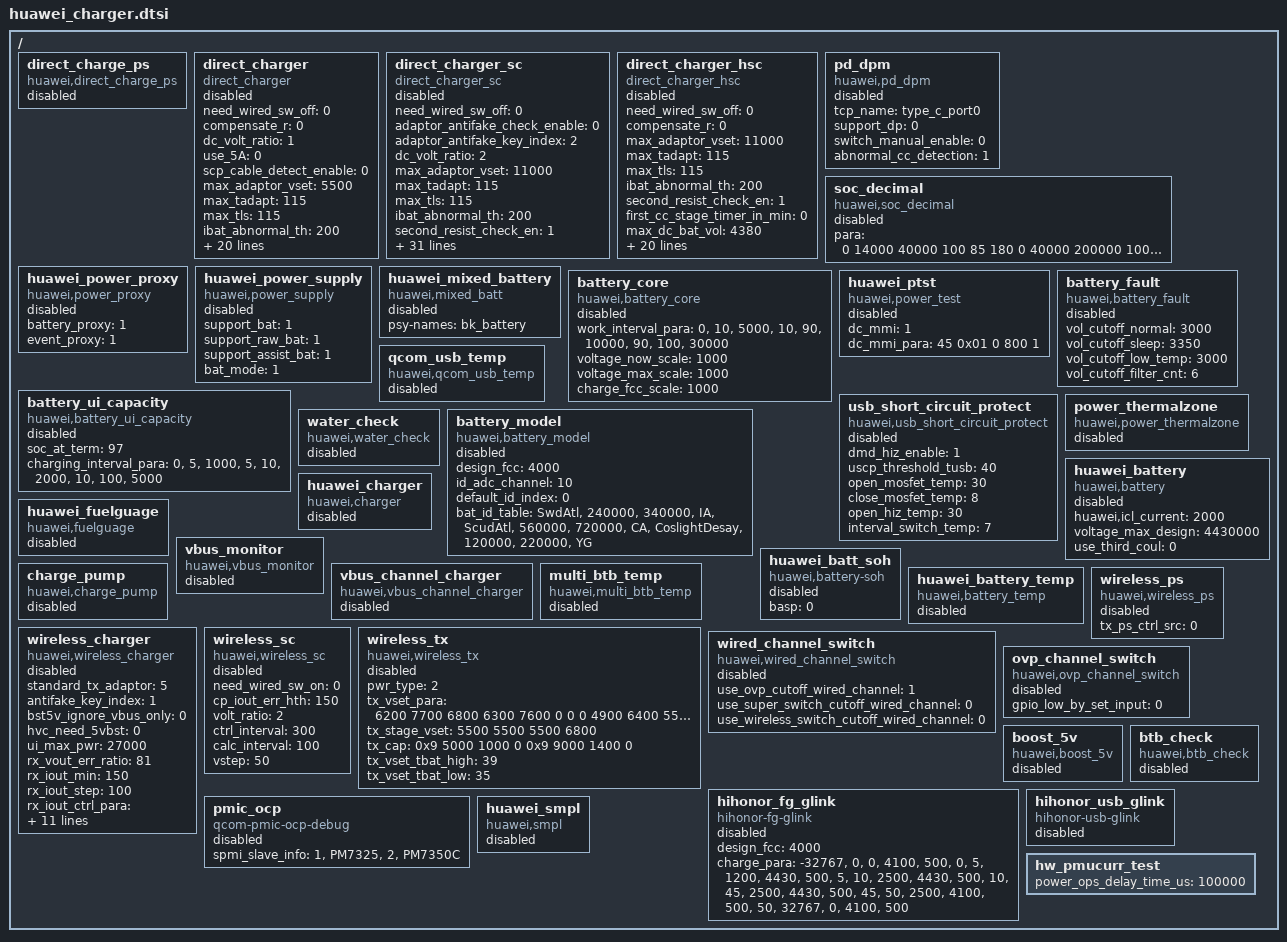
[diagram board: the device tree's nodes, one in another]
/ {
    direct_charge_ps:direct_charge_ps {
		compatible = "huawei,direct_charge_ps";
		status = "disabled";
	};

	direct_charger: direct_charger{
		need_wired_sw_off = <0>;
		compensate_r = <0>;
		dc_volt_ratio = <1>;
		use_5A = <0>;
		scp_cable_detect_enable = <0>;
		max_adaptor_vset = <5500>;
		max_tadapt = <115>;
		max_tls = <115>;
		ibat_abnormal_th = <200>;
		first_cc_stage_timer_in_min = <0>;
		max_dc_bat_vol = <4350>;
		min_dc_bat_vol = <3550>;
		is_align_caculation_work = <0>;
		charge_control_interval = <5>;
		threshold_caculation_interval = <5>;
		safety_monitor_interval = <5>;
		scp_work_on_charger = <0>;
		init_adapter_vset = <4400>;
		init_delt_vset = <300>;
		vstep = <10>;
		delta_err = <200>;
		vol_err_th = <150>;
		full_path_res_max = <120>;
		standard_cable_full_path_res_max = <160>;
		max_current_for_none_standard_cable = <3000>;
		adaptor_leakage_current_th = <300>;
		stage_need_to_jump = "-1";
		temp_para =
			"-32767", "10", "0",
			"10", "45", "4750",
			"45", "32767", "0";
		compatible = "direct_charger";
		status = "disabled";
	};
	direct_charger_sc: direct_charger_sc {
		compatible = "direct_charger_sc";
		need_wired_sw_off = <0>;
		adaptor_antifake_check_enable = <0>;
		adaptor_antifake_key_index = <2>;
		dc_volt_ratio = <2>;
		max_adaptor_vset = <11000>;
		max_tadapt = <115>;
		max_tls = <115>;
		ibat_abnormal_th = <200>;
		second_resist_check_en = <1>;
		first_cc_stage_timer_in_min = <10>;
		max_dc_bat_vol = <4380>;
		min_dc_bat_vol = <3550>;
		is_align_caculation_work = <0>;
		charge_control_interval = <5>;
		threshold_caculation_interval = <5>;
		safety_monitor_interval = <5>;
		scp_work_on_charger = <1>;
		init_adapter_vset = <8800>;
		init_delt_vset = <600>;
		vstep = <20>;
		delta_err = <300>;
		vol_err_th = <150>;
		full_path_res_max = <500>;
		standard_cable_full_path_res_max = <500>;
		max_current_for_none_standard_cable = <8000>;
		adaptor_leakage_current_th = <300>;
		stage_need_to_jump = "-1";
		compensate_r = <0>;
		cc_cable_detect_enable = <1>;
		cc_unsafe_sc_enable = <1>;
		sbu_unsafe_sc_enable = <1>;
		is_show_ico_first = <1>;
		support_multi_ic = <1>;
		ui_max_pwr = <40000>;
		volt_para =
			"4250", "8000", "6000",
			"4350", "6000", "5200",
			"4380", "5200", "4000",
			"4430", "4000", "1200";
		temp_para =
			"-32767", "10", "0",
			"10", "45", "8000",
			"45", "32767", "0";
		resist_para =
			"0", "300", "8000",
			"300", "500", "4000";
		std_resist_para =
			"0", "300", "8000",
			"300", "500", "4000";
		status = "disabled";
	};

	direct_charger_hsc: direct_charger_hsc{
		compatible = "direct_charger_hsc";
		need_wired_sw_off = <0>;
		compensate_r = <0>;
		max_adaptor_vset = <11000>;
		max_tadapt = <115>;
		max_tls = <115>;
		ibat_abnormal_th = <200>;
		second_resist_check_en = <1>;
		first_cc_stage_timer_in_min = <0>;
		max_dc_bat_vol = <4380>;
		min_dc_bat_vol = <3550>;
		is_align_caculation_work = <0>;
		charge_control_interval = <5>;
		threshold_caculation_interval = <5>;
		safety_monitor_interval = <5>;
		scp_work_on_charger = <0>;
		init_adapter_vset = <8800>;
		init_delt_vset = <600>;
		vstep = <80>;
		delta_err = <300>;
		vol_err_th = <150>;
		full_path_res_max = <120>;
		standard_cable_full_path_res_max = <160>;
		max_current_for_none_standard_cable = <6000>;
		adaptor_leakage_current_th = <300>;
		stage_need_to_jump = "-1";
		cc_unsafe_sc_enable = <1>;
		sbu_unsafe_sc_enable = <1>;
		temp_para =
			"-32767", "10", "0",
			"10", "45", "4750",
			"45", "32767", "0";
		status = "disabled";
	};

	pd_dpm: pd_dpm {
		compatible = "huawei,pd_dpm";
		tcp_name = "type_c_port0";
		support_dp = <0>;
		switch_manual_enable = <0>;
		abnormal_cc_detection = <1>;
		status = "disabled";
	};

	soc_decimal: soc_decimal {
		compatible = "huawei,soc_decimal";
		para = <
			0 14000 40000  100 85  180
			0 40000 200000 100 120 100
			1 20000 27000  100 85  140
			1 27000 200000 100 85  140
		>;
		status = "disabled";
	};

	huawei_power_proxy: huawei_power_proxy {
		compatible = "huawei,power_proxy";
		battery_proxy = <1>;
		event_proxy = <1>;
		status = "disabled";
	};

	huawei_power_supply: huawei_power_supply {
		compatible = "huawei,power_supply";
		support_bat = <1>;
		support_raw_bat = <1>;
		support_assist_bat = <1>;
		bat_mode = <1>;
		status = "disabled";
	};

	huawei_mixed_battery: huawei_mixed_battery {
		compatible = "huawei,mixed_batt";
		psy-names = "bk_battery";
		status = "disabled";
	};

	battery_core: battery_core {
		compatible = "huawei,battery_core";
		work_interval_para =
			"0","10","5000",
			"10","90","10000",
			"90","100","30000";
			voltage_now_scale = <1000>;
			voltage_max_scale = <1000>;
			charge_fcc_scale = <1000>;
			status = "disabled";
	};

    huawei_ptst: huawei_ptst {
		compatible = "huawei,power_test";
		dc_mmi = <1>;
		dc_mmi_para = <45 0x01 0 800 1>;
		status = "disabled";
    };

	battery_fault: battery_fault {
		compatible = "huawei,battery_fault";
		vol_cutoff_normal = <3000>;
		vol_cutoff_sleep = <3350>;
		vol_cutoff_low_temp = <3000>;
		vol_cutoff_filter_cnt = <6>;
		status = "disabled";
	};

	battery_ui_capacity: battery_ui_capacity {
		compatible = "huawei,battery_ui_capacity";
		soc_at_term = <97>;
		charging_interval_para =
			"0", "5", "1000",
			"5", "10", "2000",
			"10", "100", "5000";
		status = "disabled";
	};

	qcom_usb_temp: qcom_usb_temp {
		compatible = "huawei,qcom_usb_temp";
		status = "disabled";
	};

	usb_short_circuit_protect: usb_short_circuit_protect {
		compatible = "huawei,usb_short_circuit_protect";
		dmd_hiz_enable = <1>;
		uscp_threshold_tusb = <40>;
		open_mosfet_temp = <30>;
		close_mosfet_temp = <8>;
		open_hiz_temp = <30>;
		interval_switch_temp = <7>;
		status = "disabled";
	};

	power_thermalzone: power_thermalzone {
		compatible = "huawei,power_thermalzone";
		status = "disabled";
	};

	water_check: water_check {
		compatible = "huawei,water_check";
		status = "disabled";
	};

	battery_model: battery_model {
		compatible = "huawei,battery_model";
		design_fcc = <4000>;
		id_adc_channel =<10>;
		default_id_index = <0>;
		bat_id_table =
			"SwdAtl", "240000", "340000", "IA",
			"ScudAtl","560000","720000","CA",
			"CoslightDesay","120000","220000","YG";
		status = "disabled";
	};

	huawei_battery: huawei_battery {
		compatible = "huawei,battery";
		huawei,icl_current = <2000>;
		voltage_max_design = <4430000>;
		use_third_coul = <0>;
		status = "disabled";
	};

	huawei_fuelguage: huawei_fuelguage {
		compatible = "huawei,fuelguage";
		status = "disabled";
	};

	huawei_charger: huawei_charger {
		compatible = "huawei,charger";
		status = "disabled";
	};

	vbus_monitor: vbus_monitor {
		compatible = "huawei,vbus_monitor";
		status = "disabled";
	};

	huawei_batt_soh: huawei_batt_soh {
		compatible = "huawei,battery-soh";
		basp = <0>;
		status = "disabled";
	};

	vbus_channel_charger: vbus_channel_charger {
		compatible = "huawei,vbus_channel_charger";
		status = "disabled";
	};
	multi_btb_temp: multi_btb_temp {
		compatible = "huawei,multi_btb_temp";
		status = "disabled";
	};
	huawei_battery_temp: huawei_battery_temp {
		compatible = "huawei,battery_temp";
		status = "disabled";
	};
	charge_pump: charge_pump {
		compatible = "huawei,charge_pump";
		status = "disabled";
	};
	wireless_ps: wireless_ps {
		compatible = "huawei,wireless_ps";
		tx_ps_ctrl_src = <0>; /* 0:NA 1:tx_chip 2:AP */
		status = "disabled";
	};
	wireless_charger: wireless_charger {
		compatible = "huawei,wireless_charger";
		standard_tx_adaptor = <5>;/*fcp*/
		antifake_key_index = <1>;
		bst5v_ignore_vbus_only = <0>;
		hvc_need_5vbst = <0>;
		ui_max_pwr = <27000>;
		rx_vout_err_ratio = <81>; /*percent*/
		rx_iout_min = <150>;
		rx_iout_step = <100>;
		rx_iout_ctrl_para = <
			0   100  200
			100 200  300
			200 300  400
			300 400  500
			400 500  600
			500 600  700
			600 700  800
			700 800  900
			800 9999 1100
		>;
		product_para = <
			15000 18000 1600
		>;
		tx_prop =
			"0x01", "SDP",     "0", "0", "5000", "475",
			"0x02", "CDP",     "0", "0", "5000", "1000",
			"0x03", "NON_STD", "0", "0", "5000", "1000",
			"0x04", "DCP",     "0", "0", "5000", "1000",
			"0x05", "FCP",     "0", "1", "9000", "2000",
			"0x06", "SCP",     "0", "1", "5000", "1000",
			"0x07", "PD",      "0", "1", "5000", "1000",
			"0x08", "QC",      "0", "1", "5000", "1000",
			"0x09", "OTG_A",   "0", "0", "5000", "475",
			"0x0A", "OTG_B",   "0", "0", "5000", "475",
			"0xff", "ERR",     "0", "0", "5000", "1000";
		volt_mode = <
			0 5000
			1 9000
			2 12000
			3 15000
		>;
		status = "disabled";
	};
	wireless_sc: wireless_sc {
		compatible = "huawei,wireless_sc";
		need_wired_sw_on = <0>;
		cp_iout_err_hth = <150>;
		volt_ratio = <2>;
		ctrl_interval = <300>;
		calc_interval = <100>;
		vstep = <50>;
		status = "disabled";
	};
	wireless_tx: wireless_tx {
		compatible = "huawei,wireless_tx";
		pwr_type = <2>; //0:VBUS_OTG 1:5VBST_OTG 2:SP-BST
		/* rx_vmin rx_vmax tx_vset tx_lvset tx_hvset tx_pl_th tx_pl_cnt ext_hdl */
		tx_vset_para = <
			6200 7700 6800 6300 7600 0 0 0
			4900 6400 5500 5000 6300 0 0 0
			8500 10900 10000 9500 10800 0 0 0
		>;
		/* power_supply ping handshake default */
		tx_stage_vset = <5500 5500 5500 6800>;
		/* type vout iout extra */
		tx_cap = <
			0x9 5000 1000 0
			0x9 9000 1400 0
		>;
		tx_vset_tbat_high = <39>;
		tx_vset_tbat_low = <35>;
		status = "disabled";
	};
	wired_channel_switch: wired_channel_switch {
		compatible = "huawei,wired_channel_switch";
		use_ovp_cutoff_wired_channel = <1>;
		use_super_switch_cutoff_wired_channel = <0>;
		use_wireless_switch_cutoff_wired_channel = <0>;
		status = "disabled";
	};
	ovp_channel_switch: ovp_channel_switch {
		compatible = "huawei,ovp_channel_switch";
		gpio_low_by_set_input = <0>;
		status = "disabled";
	};
	boost_5v: boost_5v {
		compatible = "huawei,boost_5v";
		status = "disabled";
	};
	btb_check: btb_check {
		compatible = "huawei,btb_check";
		status = "disabled";
	};

	hihonor_fg_glink: hihonor_fg_glink {
		compatible = "hihonor-fg-glink";
		design_fcc = <4000>;
		charge_para =
			"-32767", "0", "0", "4100", "500",
			"0", "5", "1200", "4430", "500",
			"5", "10", "2500", "4430", "500",
			"10", "45", "2500", "4430", "500",
			"45", "50", "2500", "4100", "500",
			"50", "32767", "0", "4100", "500";
		status = "disabled";
	};

	hihonor_usb_glink: hihonor_usb_glink {
		compatible = "hihonor-usb-glink";
		status = "disabled";
	};

	pmic_ocp: pmic_ocp {
		compatible = "qcom-pmic-ocp-debug";
		spmi_slave_info =
			/* spmi_sid, name */
			"1", "PM7325",
			"2", "PM7350C";
		status = "disabled";
	};
	hw_pmucurr_test: hw_pmucurr_test {
		power_ops_delay_time_us = "100000";
	};

	huawei_smpl: huawei_smpl{
		compatible = "huawei,smpl";
		status = "disabled";
	};
};
